# LPC55S16 register map
Vendor: nxp.com; File version: 1.0
CPU: CM33 r2p0, little endian, MPU, FPU, VTOR, 3 interrupt priority bits
Registers are 32-bit, read-write, reset 0x0 unless marked. A register's access mark holds for its fields unless they carry their own. Offsets are from the block's base; [hi:lo] are bit positions; {n}, {i} and the like mark numbered series; 'fields as' and 'values as' point back to an identical list.

## FLASH_CMPA
Base 0x0003E400
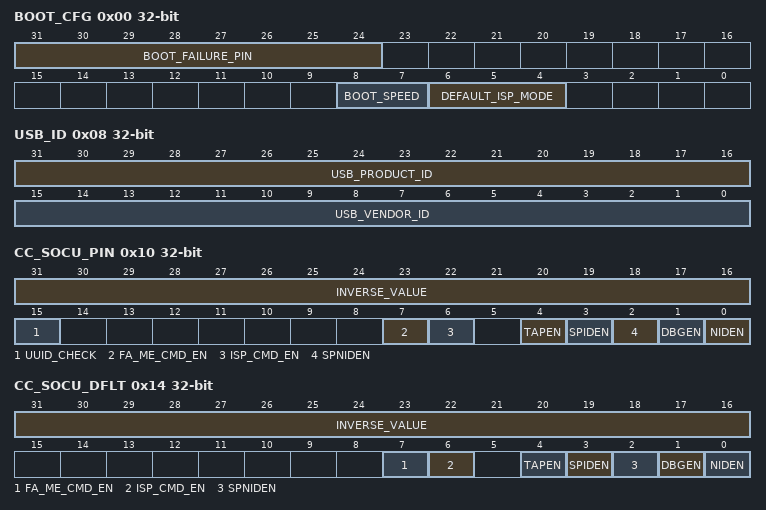
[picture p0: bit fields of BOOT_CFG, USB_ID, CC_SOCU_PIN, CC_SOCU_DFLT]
0x00 BOOT_CFG
  [31:24] BOOT_FAILURE_PIN — GPIO port and pin number to use for indicating failure reason. The toggle rate of the pin is used to decode the error type. [2:0] - Defines GPIO port [7:3] - Defines GPIO pin
  [8:7] BOOT_SPEED — Core clock:
    0=Defined by NMPA.SYSTEM_SPEED_CODE; 2=48MHz FRO
  [6:4] DEFAULT_ISP_MODE
    0=AUTO_ISP; 1=USB_HID_ISP; 2=UART_ISP; 3=SPI_ISP (SPI Slave ISP); 4=I2C_ISP (I2C Slave ISP); 7=DISABLE (Disable ISP fall through)
0x04 SPI_FLASH_CFG
  [4:0] SPI_RECOVERY_BOOT_EN — SPI flash recovery boot is enabled, if non-zero value is written to this field.
0x08 USB_ID
  [31:16] USB_PRODUCT_ID, [15:0] USB_VENDOR_ID
0x0C SDIO_CFG
  [31:0] FIELD
0x10 CC_SOCU_PIN
  [31:16] INVERSE_VALUE — inverse value of bits [15:0]
  [15] UUID_CHECK — Enforce UUID match during Debug authentication.
  [7] FA_ME_CMD_EN — FA Command enable
    0=ENABLE (Use DAP to enable); 1=DISABLE (Fixed state)
  [6] ISP_CMD_EN — ISP Boot Command enable
    0=ENABLE (Use DAP to enable); 1=DISABLE (Fixed state)
  [4] TAPEN — JTAG TAP enable
    0=ENABLE (Use DAP to enable); 1=DISABLE (Fixed state)
  [3] SPIDEN — Secure invasive debug enable
    0=ENABLE (Use DAP to enable); 1=DISABLE (Fixed state)
  [2] SPNIDEN — Secure non-invasive debug enable
    0=ENABLE (Use DAP to enable); 1=DISABLE (Fixed state)
  [1] DBGEN — Non Secure debug enable
    0=ENABLE (Use DAP to enable); 1=DISABLE (Fixed state)
  [0] NIDEN — Non Secure non-invasive debug enable
    0=ENABLE (Use DAP to enable); 1=DISABLE (Fixed state)
0x14 CC_SOCU_DFLT
  [31:16] INVERSE_VALUE — inverse value of bits [15:0]
  [7] FA_ME_CMD_EN — FA Command fixed state
    0=DISABLE; 1=ENABLE
  [6] ISP_CMD_EN — ISP Boot Command fixed state
    0=DISABLE; 1=ENABLE
  [4] TAPEN — JTAG TAP fixed state
    0=DISABLE; 1=ENABLE
  [3] SPIDEN — Secure invasive debug fixed state
    0=DISABLE; 1=ENABLE
  [2] SPNIDEN — Secure non-invasive debug fixed state
    0=DISABLE; 1=ENABLE
  [1] DBGEN — Non Secure debug fixed state
    0=DISABLE; 1=ENABLE
  [0] NIDEN — Non Secure non-invasive debug fixed state
    0=DISABLE; 1=ENABLE
0x18 VENDOR_USAGE
  [31:16] VENDOR_USAGE — Upper 16 bits of vendor usage field defined in DAP. Lower 16-bits come from customer field area.
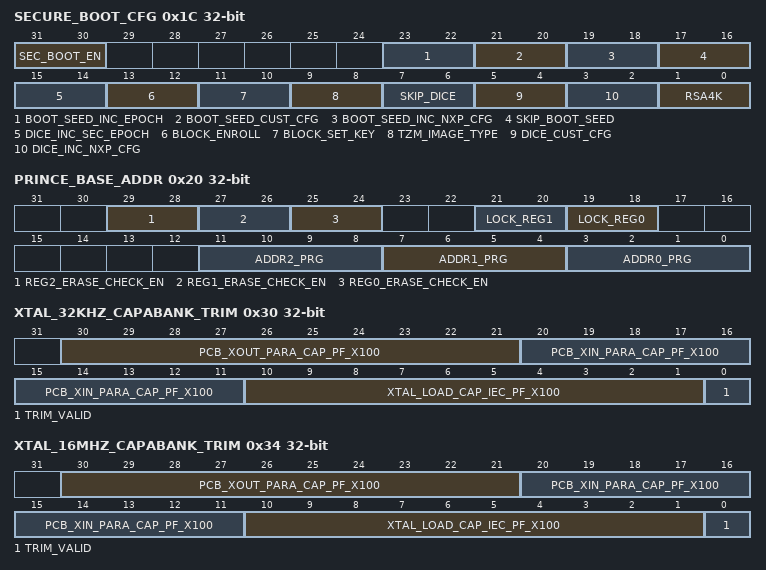
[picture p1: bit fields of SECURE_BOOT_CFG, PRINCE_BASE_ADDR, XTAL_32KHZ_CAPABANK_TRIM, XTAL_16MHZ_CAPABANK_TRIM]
0x1C SECURE_BOOT_CFG — Secure boot configuration flags.
  [31:30] SEC_BOOT_EN — Secure boot enable
    0=DISABLE (Plain image (internal flash with or without CRC)); 1=ENABLE (Boot signed images. (internal flash, RSA signed)); 2=Boot signed images. (internal flash, RSA signed); 3=Boot signed images. (internal flash, RSA signed)
  [23:22] BOOT_SEED_INC_EPOCH — Include security epoch area in BOOT_SEED computation.
    0=NOT_INCLUD (not included); 1=INCLUD (included); 2=included; 3=included
  [21:20] BOOT_SEED_CUST_CFG — Include CMPA area in BOOT SEED computation
    values as BOOT_SEED_INC_EPOCH
  [19:18] BOOT_SEED_INC_NXP_CFG — Include NXP area in BOOT SEED computation
    values as BOOT_SEED_INC_EPOCH
  [17:16] SKIP_BOOT_SEED — Skip boot seed computation
    0=ENABLE (Enable BOOT_SEED); 1=DISABLE (Disable BOOT_SEED); 2=Disable BOOT_SEED; 3=Disable BOOT_SEED
  [15:14] DICE_INC_SEC_EPOCH — Include security EPOCH in DICE
    values as BOOT_SEED_INC_EPOCH
  [13:12] BLOCK_ENROLL — Block PUF enrollement
    0=ALLOW (Allow PUF enroll operation); 1=DISABLE (Disable PUF enroll operation); 2=Disable PUF enroll operation; 3=Disable PUF enroll operation
  [11:10] BLOCK_SET_KEY — Block PUF key code generation
    0=ALLOW (Allow PUF Key Code generation); 1=DISABLE (Disable PUF Key Code generation); 2=Disable PUF Key Code generation; 3=Disable PUF Key Code generation
  [9:8] TZM_IMAGE_TYPE — TrustZone-M mode
    0=TZ-M image mode is taken from application image header; 1=TZ-M disabled image, boots to non-secure mode; 2=TZ-M enabled image, boots to secure mode; 3=TZ-M enabled image with TZ-M preset, boot to secure mode TZ-M pre-configured by data from application image header
  [7:6] SKIP_DICE — Skip DICE computation
    0=ENABLE (Enable DICE); 1=DISABLE (Disable DICE); 2=Disable DICE; 3=Disable DICE
  [5:4] DICE_CUST_CFG — Include Customer factory area (including keys) in DICE computation.
    0=NOT_INCLUD (not included); 1=UNCLUD (included); 2=included; 3=included
  [3:2] DICE_INC_NXP_CFG — Include NXP area in DICE computation.
    values as BOOT_SEED_INC_EPOCH
  [1:0] RSA4K — Use RSA4096 keys only.
    0=Allow RSA2048 and higher; 1=RSA4096 only; 2=RSA4096 only; 3=RSA4096 only
0x20 PRINCE_BASE_ADDR
  [29:28] REG2_ERASE_CHECK_EN — For PRINCE region2 enable checking whether all encrypted pages are erased together
    0=DISABLE (Region is disabled); 1=ENABLE (Region is enabled); 2=Region is enabled; 3=Region is enabled
  [27:26] REG1_ERASE_CHECK_EN — For PRINCE region1 enable checking whether all encrypted pages are erased together
    values as REG2_ERASE_CHECK_EN
  [25:24] REG0_ERASE_CHECK_EN — For PRINCE region0 enable checking whether all encrypted pages are erased together
    values as REG2_ERASE_CHECK_EN
  [21:20] LOCK_REG1 — Lock PRINCE region1 settings
    0=UNLOCK (Region is not locked); 1=LOCK (Region is locked); 2=Region is locked; 3=Region is locked
  [19:18] LOCK_REG0 — Lock PRINCE region0 settings
    values as LOCK_REG1
  [11:8] ADDR2_PRG — Programmable portion of the base address of region 2
  [7:4] ADDR1_PRG — Programmable portion of the base address of region 1
  [3:0] ADDR0_PRG — Programmable portion of the base address of region 0
{0x24+4i} PRINCE_SR_{i} (i=0..2) — Region {i}, sub-region enable
  [31:0] FIELD
0x30 XTAL_32KHZ_CAPABANK_TRIM — Xtal 32kHz capabank triming.
  [30:21] PCB_XOUT_PARA_CAP_PF_X100 — PCB XOUT parasitic capacitance, pF x 100. For example, 6pF becomes 600.
  [20:11] PCB_XIN_PARA_CAP_PF_X100 — PCB XIN parasitic capacitance, pF x 100. For example, 6pF becomes 600.
  [10:1] XTAL_LOAD_CAP_IEC_PF_X100 — Load capacitance, pF x 100. For example, 6pF becomes 600.
  [0] TRIM_VALID — XTAL 32kHz capa bank trimmings
    0=NOT_TRIM (Capa Bank trimmings not valid. Default trimmings value are used); 1=VALID (Capa Bank trimmings valid)
0x34 XTAL_16MHZ_CAPABANK_TRIM — Xtal 16MHz capabank triming.
  [30:21] PCB_XOUT_PARA_CAP_PF_X100 — PCB XOUT parasitic capacitance, pF x 100. For example, 6pF becomes 600.
  [20:11] PCB_XIN_PARA_CAP_PF_X100 — PCB XIN parasitic capacitance, pF x 100. For example, 6pF becomes 600.
  [10:1] XTAL_LOAD_CAP_IEC_PF_X100 — Load capacitance, pF x 100. For example, 6pF becomes 600.
  [0] TRIM_VALID — XTAL 16MHz capa bank trimmings
    values as XTAL_32KHZ_CAPABANK_TRIM.TRIM_VALID
0x38 FLASH_REMAP_SIZE — This 32-bit register contains the size of the image to remap, in bytes. The 12 LSBs are ignored, so the size granularity is 4KB.
  [31:0] FIELD
0x3C FLASH_REMAP_OFFSET — This 32-bit register contains the offset by which the image is to be remapped. The 12 LSBs are ignored, so the remap granularity is 4KB.
  [31:0] FIELD
{0x50+4i} ROTKH[{i}] (i=0..7) — ROTKHindex for Root of Trust Keys Table hash[(((7 - index) * 32) + 31):((7 - index) * 32)]
  [31:0] FIELD
{0x100+4i} CUSTOMER_DEFINED[{i}] (i=0..55) — Customer Defined (Programable through ROM API)
  [31:0] FIELD
{0x1E0+4i} SHA256_DIGEST[{i}] (i=0..7) — SHA256_DIGESTindex for DIGEST[((index * 32) + 31):(index * 32)]
  [31:0] FIELD
